# CH32V407 register map
Vendor: WCH Ltd.; File version: 1.0
Registers are 32-bit, read-write, reset 0x0 unless marked. A register's access mark holds for its fields unless they carry their own. Offsets are from the block's base; [hi:lo] are bit positions.

## SPI1 — Serial peripheral interface
Base 0x40013000
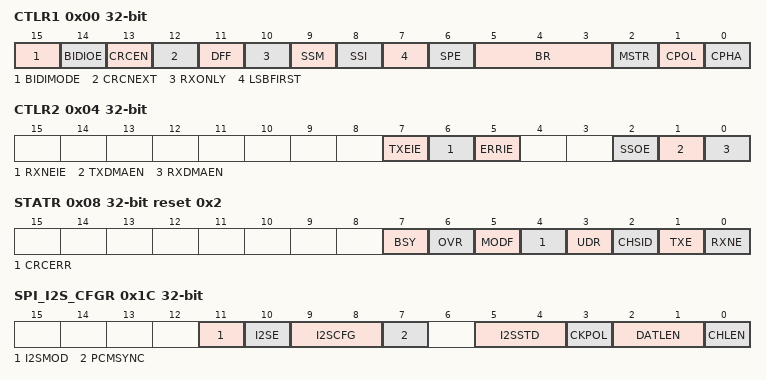
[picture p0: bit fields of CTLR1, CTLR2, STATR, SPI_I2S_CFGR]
0x00 CTLR1 — control register 1
  [15] BIDIMODE — Bidirectional data mode enable
  [14] BIDIOE — Output enable in bidirectional mode
  [13] CRCEN — Hardware CRC calculation enable
  [12] CRCNEXT — CRC transfer next
  [11] DFF — Data frame format
  [10] RXONLY — Receive only
  [9] SSM — Software slave management
  [8] SSI — Internal slave select
  [7] LSBFIRST — Frame format
  [6] SPE — SPI enable
  [5:3] BR — Baud rate control
  [2] MSTR — Master selection
  [1] CPOL — Clock polarity
  [0] CPHA — Clock phase
0x04 CTLR2 — control register 2
  [7] TXEIE — Tx buffer empty interrupt enable
  [6] RXNEIE — RX buffer not empty interrupt enable
  [5] ERRIE — Error interrupt enable
  [2] SSOE — SS output enable
  [1] TXDMAEN — Tx buffer DMA enable
  [0] RXDMAEN — Rx buffer DMA enable
0x08 STATR access per field reset 0x2 — status register
  [7] BSY ro — Busy flag
  [6] OVR ro — Overrun flag
  [5] MODF ro — Mode fault
  [4] CRCERR rw — CRC error flag
  [3] UDR ro — Underrun flag
  [2] CHSID ro — Channel side
  [1] TXE ro — Transmit buffer empty
  [0] RXNE ro — Receive buffer not empty
0x0C DATAR — data register
  [15:0] DR — Data register
0x10 CRCR reset 0x7 — CRCR polynomial register
  [15:0] CRCPOLY — CRC polynomial register
0x14 RCRCR ro — RX CRC register
  [15:0] RXCRC
0x18 TCRCR ro — TX CRC register
  [15:0] TXCRC
0x1C SPI_I2S_CFGR — SPI_I2S configure register
  [11] I2SMOD — I2S mode selection
  [10] I2SE — I2S Enable
  [9:8] I2SCFG — I2SCFG[1:0] bits (I2S configuration mode)
  [7] PCMSYNC — PCM frame synchronization
  [5:4] I2SSTD — I2SSTD[1:0] bits (I2S standard selection)
  [3] CKPOL — steady state clock polarity
  [2:1] DATLEN — DATLEN[1:0] bits (Data length to be transferred)
  [0] CHLEN — Channel length (number of bits per audio channel)
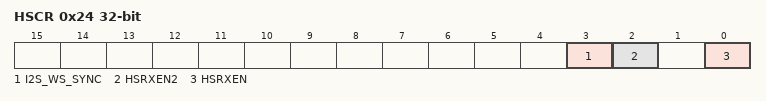
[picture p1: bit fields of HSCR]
0x24 HSCR — high speed control register
  [3] I2S_WS_SYNC — Enable the enhanced synchronization capability of I2S as a slave device
  [2] HSRXEN2 — High speed mode 2 read enable
  [0] HSRXEN — High speed mode read enable

## SPI2 — Serial peripheral interface
Base 0x40003800
Same registers: SPI3 0x40003C00
Registers as SPI1, without SPI_I2S_CFGR; these are added or differ:
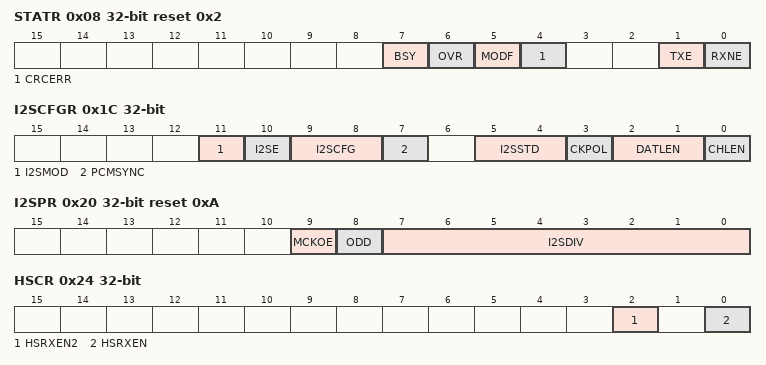
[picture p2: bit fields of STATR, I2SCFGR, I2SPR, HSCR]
0x08 STATR access per field reset 0x2 — status register
  [7] BSY ro — Busy flag
  [6] OVR ro — Overrun flag
  [5] MODF ro — Mode fault
  [4] CRCERR rw — CRC error flag
  [1] TXE ro — Transmit buffer empty
  [0] RXNE ro — Receive buffer not empty
0x1C I2SCFGR — I2S configuration register
  [11] I2SMOD — I2S mode selection
  [10] I2SE — I2S Enable
  [9:8] I2SCFG — I2S configuration mode
  [7] PCMSYNC — PCM frame synchronization
  [5:4] I2SSTD — I2S standard selection
  [3] CKPOL — Steady state clock polarity
  [2:1] DATLEN — Data length to be transferred
  [0] CHLEN — Channel length (number of bits per audio channel)
0x20 I2SPR reset 0xA — I2S prescaler register
  [9] MCKOE — Master clock output enable
  [8] ODD — Odd factor for the prescaler
  [7:0] I2SDIV — I2S Linear prescaler
0x24 HSCR — high speed control register
  [2] HSRXEN2 — High speed mode 2 read enable
  [0] HSRXEN — High speed mode read enable

## DVP — Digital Video Port
Base 0x50050000
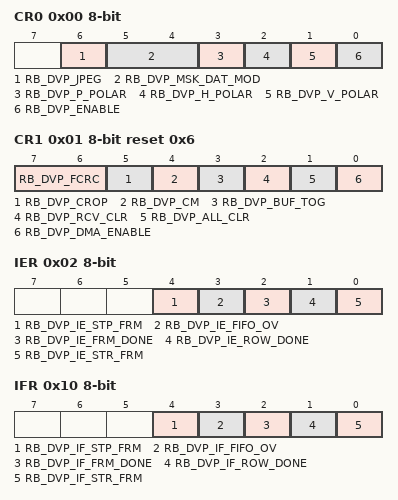
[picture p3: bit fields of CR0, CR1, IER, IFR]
0x00 CR0 8-bit — Digital Video control register (DVP_CR0)
  [6] RB_DVP_JPEG — DVP JPEG mode
  [5:4] RB_DVP_MSK_DAT_MOD — DVP data mode
  [3] RB_DVP_P_POLAR — DVP PCLK polarity control
  [2] RB_DVP_H_POLAR — DVP HSYNC polarity control
  [1] RB_DVP_V_POLAR — DVP VSYNC polarity control
  [0] RB_DVP_ENABLE — DVP enable
0x01 CR1 8-bit reset 0x6 — Digital Video control register (DVP_CR1)
  [7:6] RB_DVP_FCRC — DVP frame capture rate control
  [5] RB_DVP_CROP — DVP Crop feature enable
  [4] RB_DVP_CM — DVP capture mode
  [3] RB_DVP_BUF_TOG — DVP bug toggle by software
  [2] RB_DVP_RCV_CLR — DVP receive logic clear
  [1] RB_DVP_ALL_CLR — DVP all clear
  [0] RB_DVP_DMA_ENABLE — DVP dma enable
0x02 IER 8-bit — Digital Video Interrupt register (DVP_IER)
  [4] RB_DVP_IE_STP_FRM — DVP frame stop interrupt enable
  [3] RB_DVP_IE_FIFO_OV — DVP receive fifo overflow interrupt enable
  [2] RB_DVP_IE_FRM_DONE — DVP frame received done interrupt enable
  [1] RB_DVP_IE_ROW_DONE — DVP row received done interrupt enable
  [0] RB_DVP_IE_STR_FRM — DVP frame start interrupt enable
0x04 ROW_NUM 16-bit — Image line count configuration register (DVP_ROW_NUM)
  [15:0] RB_DVP_ROW_NUM — The number of rows of frame image data
0x06 COL_NUM 16-bit — Image column number configuration register (DVP_COL_NUM)
  [15:0] RB_DVP_COL_NUM — Number of PCLK cycles for row data
0x08 DMA_BUF0 — Digital Video DMA address register (DVP_DMA_BUF0)
  [31:0] RB_DVP_DMA_BUF0 — DMA receive address 0
0x0C DMA_BUF1 — Digital Video DMA address register (DVP_DMA_BUF1)
  [31:0] RB_DVP_DMA_BUF1 — DMA receive address 1
0x10 IFR 8-bit — Digital Video Flag register (DVP_IFR)
  [4] RB_DVP_IF_STP_FRM — DVP frame stop interrupt enable
  [3] RB_DVP_IF_FIFO_OV — DVP receive fifo overflow interrupt enable
  [2] RB_DVP_IF_FRM_DONE — DVP frame received done interrupt enable
  [1] RB_DVP_IF_ROW_DONE — DVP row received done interrupt enable
  [0] RB_DVP_IF_STR_FRM — DVP frame start interrupt enable
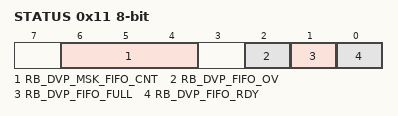
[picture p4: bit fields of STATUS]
0x11 STATUS 8-bit ro — Digital Video STATUS register (DVP_STATUS)
  [6:4] RB_DVP_MSK_FIFO_CNT — DVP receive fifo overflow interrupt enable
  [2] RB_DVP_FIFO_OV — DVP frame received done interrupt enable
  [1] RB_DVP_FIFO_FULL — DVP row received done interrupt enable
  [0] RB_DVP_FIFO_RDY — DVP frame start interrupt enable
0x14 ROW_CNT 16-bit ro — Digital Video line counter register (DVP_ROW_CNT)
  [15:0] RB_DVP_ROW_CNT — The number of rows of frame image data
0x18 HOFFCNT 16-bit — Digital Video horizontal displacement register (DVP_HOFFCNT)
  [15:0] RB_DVP_HOFFCNT — Number of PCLK cycles for row data
0x1A VST 16-bit — Digital Video line number register (DVP_VST)
  [15:0] RB_DVP_VST — The number of lines captured by the image
0x1C CAPCNT 16-bit — Digital Video Capture count register (DVP_CAPCNT)
  [15:0] RB_DVP_CAPCNT — Number of PCLK cycles captured by clipping window
0x1E VLINE 16-bit — Digital Video Vertical line count register (DVP_VLINE)
  [15:0] RB_DVP_VLINE — Crop the number of rows captured by window
0x20 DR ro — Digital Video Data register (DVP_DR)
  [31:0] RB_DVP_DR — Prevent DMA overflow
